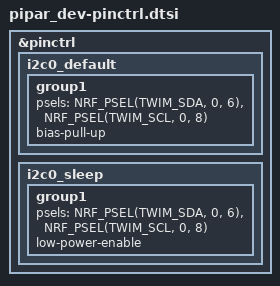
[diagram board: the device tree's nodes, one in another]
&pinctrl {
    /* I2C0 for nPM1300 — SDA=P0.06, SCL=P0.08 (per dev PCB schematic) */
    i2c0_default: i2c0_default {
        group1 {
            psels = <NRF_PSEL(TWIM_SDA, 0, 6)>,
                    <NRF_PSEL(TWIM_SCL, 0, 8)>;
            bias-pull-up;
        };
    };

    i2c0_sleep: i2c0_sleep {
        group1 {
            psels = <NRF_PSEL(TWIM_SDA, 0, 6)>,
                    <NRF_PSEL(TWIM_SCL, 0, 8)>;
            low-power-enable;
        };
    };
};
